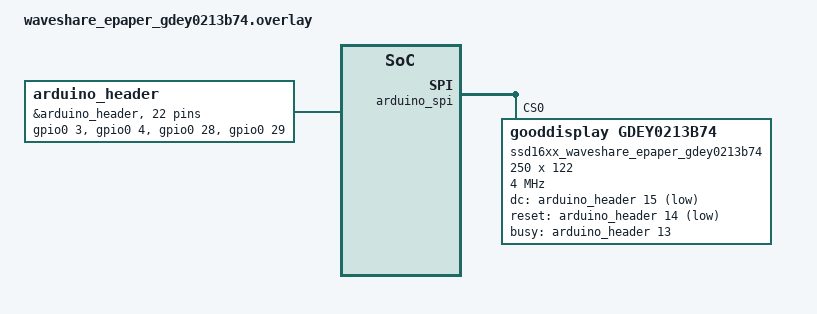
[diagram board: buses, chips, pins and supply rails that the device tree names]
/*
 * Copyright (c) 2024, Kelly Helmut Lord
 *
 * SPDX-License-Identifier: Apache-2.0
 */

#include "waveshare_epaper_common.dtsi"

/ {
	chosen {
		zephyr,display = &ssd16xx_waveshare_epaper_gdey0213b74;
	};
};

&arduino_spi {
	ssd16xx_waveshare_epaper_gdey0213b74: ssd16xxfb@0 {
		compatible = "gooddisplay,gdey0213b74", "solomon,ssd1680";
		spi-max-frequency = <4000000>;
		reg = <0>;
		width = <250>;
		height = <122>;
		dc-gpios = <&arduino_header 15 GPIO_ACTIVE_LOW>;	/* D9 */
		reset-gpios = <&arduino_header 14 GPIO_ACTIVE_LOW>;	/* D8 */
		busy-gpios = <&arduino_header 13 GPIO_ACTIVE_HIGH>;	/* D7 */

		tssv = <0x80>;

		full {
			border-waveform = <0x05>;
		};

		partial {
			border-waveform = <0x3c>;
		};
	};
};

&arduino_header {
	gpio-map = <0 0 &gpio0 3 0>,
			   <1 0 &gpio0 4 0>,
			   <2 0 &gpio0 28 0>,
			   <3 0 &gpio0 29 0>,
			   <4 0 &gpio0 30 0>,
			   <5 0 &gpio0 31 0>,
			   <6 0 &gpio1 1 0>,
			   <7 0 &gpio1 2 0>,
			   <8 0 &gpio1 3 0>,
			   <9 0 &gpio1 4 0>,
			   <10 0 &gpio1 5 0>,
			   <11 0 &gpio1 6 0>,
			   <12 0 &gpio1 7 0>,
			   <13 0 &gpio1 8 0>,
			   <14 0 &gpio1 10 0>,
			   <15 0 &gpio1 11 0>,
			   <16 0 &gpio1 12 0>,
			   <17 0 &gpio1 13 0>,
			   <18 0 &gpio1 14 0>,
			   <19 0 &gpio1 15 0>,
			   <20 0 &gpio0 26 0>,
			   <21 0 &gpio0 27 0>;
};

&arduino_adc {
	io-channel-map = <0 &adc 1>, <1 &adc 2>, <2 &adc 4>, <3 &adc 5>, <4 &adc 6>, <5 &adc 7>;
};
